# f2838x_cm_dcsm_common_regs register map
Vendor: Texas Instruments
Peripheral module from a debugger description file (folder C2000).
Address unit: 16 bits
Registers are 32-bit, read-only, no defined reset value unless marked. A register's access mark holds for its fields unless they carry their own. Offsets are as the file gives them; lines under a group give offsets from that group; [hi:lo] are bit positions; {n}, {i} and the like mark numbered series; 'fields as' and 'values as' point back to an identical list; <NAME> marks a mode.

## DCSM_COMMON_REGS — DCSM COMMON Registers
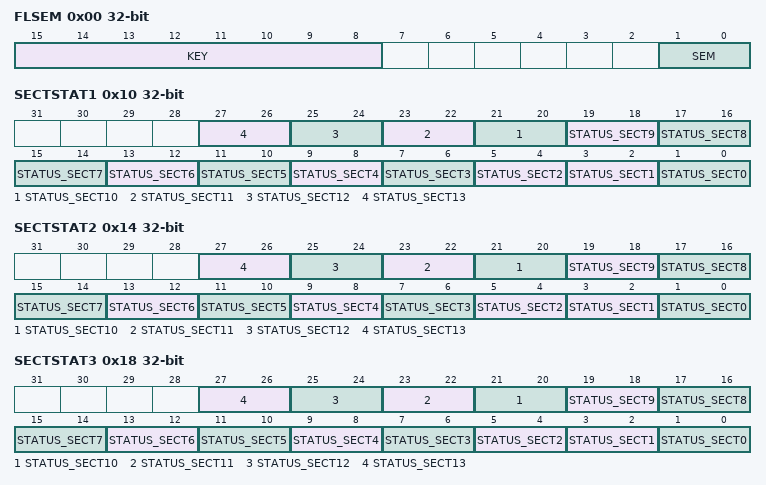
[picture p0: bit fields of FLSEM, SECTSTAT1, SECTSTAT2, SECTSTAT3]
0x00 FLSEM rw — Flash Wrapper Semaphore Register
  [15:8] KEY — Semaphore Key
  [1:0] SEM — Flash Semaphore Bit
0x10 SECTSTAT1 — Flash Sectors Status Register 1
  [2n+1:2n] STATUS_SECT{n} (n=9..13) — Zone Status flash CPU1 BANK Sector {n}
  [17:16] STATUS_SECT8 — Zone Status flash CPU1 BANK sector 8
  [2n+1:2n] STATUS_SECT{n} (n=2..7) — Zone Status flash CPU1 BANK Sector {n}
  [3:2] STATUS_SECT1 — Zone Status flash CPU1 BANK sector 1
  [1:0] STATUS_SECT0 — Zone Status flash CPU1 BANK Sector 0
0x14 SECTSTAT2 — Flash Sectors Status Register 2
  [2n+1:2n] STATUS_SECT{n} (n=9..13) — Zone Status flash CM BANK Sector {n}
  [17:16] STATUS_SECT8 — Zone Status flash CM BANK sector 8
  [2n+1:2n] STATUS_SECT{n} (n=2..7) — Zone Status flash CM BANK Sector {n}
  [3:2] STATUS_SECT1 — Zone Status flash CM BANK sector 1
  [1:0] STATUS_SECT0 — Zone Status flash CM BANK Sector 0
0x18 SECTSTAT3 — Flash Sectors Status Register 3
  [2n+1:2n] STATUS_SECT{n} (n=9..13) — Zone Status flash CPU2 BANK Sector {n}
  [17:16] STATUS_SECT8 — Zone Status flash CPU2 BANK sector 8
  [2n+1:2n] STATUS_SECT{n} (n=2..7) — Zone Status flash CPU2 BANK Sector {n}
  [3:2] STATUS_SECT1 — Zone Status flash CPU2 BANK sector 1
  [1:0] STATUS_SECT0 — Zone Status flash CPU2 BANK Sector 0
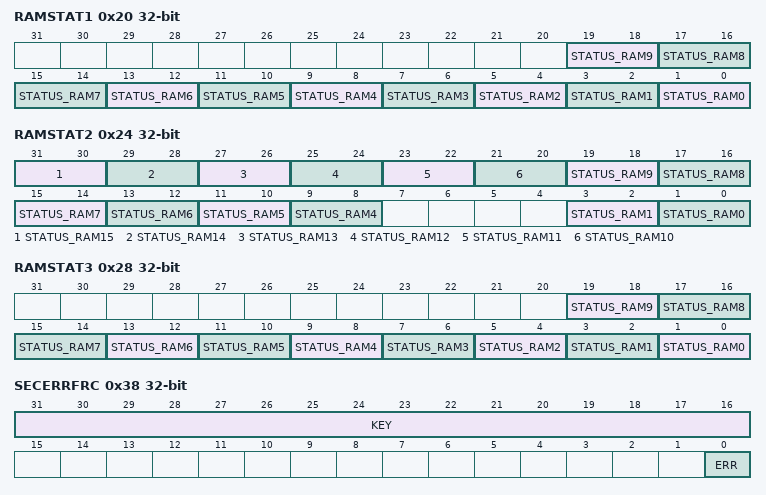
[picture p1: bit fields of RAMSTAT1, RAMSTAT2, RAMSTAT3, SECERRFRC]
0x20 RAMSTAT1 — RAM Status Register 1
  [19:18] STATUS_RAM9 — Zone Status RAM CPU1.D1
  [17:16] STATUS_RAM8 — Zone Status RAM CPU1.D0
  [2n+1:2n] STATUS_RAM{n} (n=0..7) — Zone Status RAM CPU1.LS{n}
0x24 RAMSTAT2 — RAM Status Register 2
  [31:30] STATUS_RAM15 — Zone Status RAM CPU2 to CPU1 MSG RAM 2
  [29:28] STATUS_RAM14 — Zone Status RAM CPU2 to CPU1 MSG RAM 1
  [27:26] STATUS_RAM13 — Zone Status RAM CPU1 to CPU2 MSG RAM 2
  [25:24] STATUS_RAM12 — Zone Status RAM CPU1 to CPU2 MSG RAM 1
  [23:22] STATUS_RAM11 — Zone Status RAM CM to CPU2 MSG RAM 2
  [21:20] STATUS_RAM10 — Zone Status RAM CM to CPU2 MSG RAM 1
  [19:18] STATUS_RAM9 — Zone Status RAM CPU2 to CM MSG RAM 2
  [17:16] STATUS_RAM8 — Zone Status RAM CPU2 to CM MSG RAM 1
  [15:14] STATUS_RAM7 — Zone Status RAM CM to CPU1 MSG RAM 2
  [13:12] STATUS_RAM6 — Zone Status RAM CM to CPU1 MSG RAM 1
  [11:10] STATUS_RAM5 — Zone Status RAM CPU1 to CM MSG RAM 2
  [9:8] STATUS_RAM4 — Zone Status RAM CPU1 to CM MSG RAM 1
  [3:2] STATUS_RAM1 — Zone Status RAM CM.C1
  [1:0] STATUS_RAM0 — Zone Status RAM CM.C0
0x28 RAMSTAT3 — RAM Status Register 3
  [19:18] STATUS_RAM9 — Zone Status RAM CPU2.D1
  [17:16] STATUS_RAM8 — Zone Status RAM CPU2.D0
  [2n+1:2n] STATUS_RAM{n} (n=0..7) — Zone Status RAM CPU2.LS{n}
0x30 SECERRSTAT — Security Error Status Register
  [0] ERR — Security Configuration load Error Status
0x34 SECERRCLR rw — Security Error Clear Register
  [0] ERR — Clear Security Configuration Load Error Status Bit
0x38 SECERRFRC rw — Security Error Force Register
  [31:16] KEY — Valid Register Write Key
  [0] ERR — Set Security Configuration Load Error Status Bit
